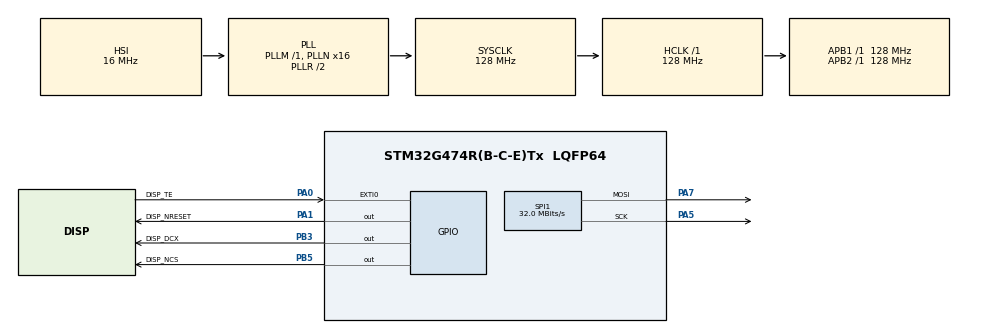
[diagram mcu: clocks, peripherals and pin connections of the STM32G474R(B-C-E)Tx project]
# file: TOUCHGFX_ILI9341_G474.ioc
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Dma.Request0=SPI1_TX
Dma.SPI1_TX.0.Direction=DMA_MEMORY_TO_PERIPH
Dma.SPI1_TX.0.EventEnable=DISABLE
Dma.SPI1_TX.0.Instance=DMA1_Channel1
Dma.SPI1_TX.0.MemDataAlignment=DMA_MDATAALIGN_HALFWORD
Dma.SPI1_TX.0.MemInc=DMA_MINC_ENABLE
Dma.SPI1_TX.0.Mode=DMA_NORMAL
Dma.SPI1_TX.0.PeriphDataAlignment=DMA_PDATAALIGN_HALFWORD
Dma.SPI1_TX.0.PeriphInc=DMA_PINC_DISABLE
Dma.SPI1_TX.0.Polarity=HAL_DMAMUX_REQ_GEN_RISING
Dma.SPI1_TX.0.Priority=DMA_PRIORITY_LOW
Dma.SPI1_TX.0.RequestNumber=1
Dma.SPI1_TX.0.SignalID=NONE
Dma.SPI1_TX.0.SyncEnable=DISABLE
Dma.SPI1_TX.0.SyncPolarity=HAL_DMAMUX_SYNC_NO_EVENT
Dma.SPI1_TX.0.SyncRequestNumber=1
Dma.SPI1_TX.0.SyncSignalID=NONE
Mcu.Family=STM32G4
Mcu.Name=STM32G474R(B-C-E)Tx
Mcu.Package=LQFP64
NVIC.DMA1_Channel1_IRQn=true\:0\:0\:false\:false\:true\:false\:true\:true
NVIC.EXTI0_IRQn=true\:0\:0\:false\:false\:true\:true\:true\:true
NVIC.PriorityGroup=NVIC_PRIORITYGROUP_4
PA0.GPIO_Label=DISP_TE
PA0.GPIO_ModeDefaultEXTI=GPIO_MODE_IT_RISING_FALLING
PA0.Signal=GPXTI0
PA1.GPIO_Label=DISP_NRESET
PA1.GPIO_PuPd=GPIO_PULLUP
PA1.GPIO_Speed=GPIO_SPEED_FREQ_VERY_HIGH
PA1.Signal=GPIO_Output
PA5.GPIO_Mode=GPIO_MODE_AF_PP
PA5.GPIO_PuPd=GPIO_PULLDOWN
PA5.GPIO_Speed=GPIO_SPEED_FREQ_HIGH
PA5.Mode=TX_Only_Simplex_Unidirect_Master
PA5.Signal=SPI1_SCK
PA7.GPIO_Mode=GPIO_MODE_AF_PP
PA7.GPIO_PuPd=GPIO_PULLDOWN
PA7.GPIO_Speed=GPIO_SPEED_FREQ_HIGH
PA7.Mode=TX_Only_Simplex_Unidirect_Master
PA7.Signal=SPI1_MOSI
PB3.GPIO_Label=DISP_DCX
PB3.GPIO_PuPd=GPIO_PULLUP
PB3.GPIO_Speed=GPIO_SPEED_FREQ_VERY_HIGH
PB3.PinState=GPIO_PIN_SET
PB3.Signal=GPIO_Output
PB5.GPIO_Label=DISP_NCS
PB5.GPIO_PuPd=GPIO_PULLUP
PB5.GPIO_Speed=GPIO_SPEED_FREQ_VERY_HIGH
PB5.PinState=GPIO_PIN_SET
PB5.Signal=GPIO_Output
ProjectManager.HeapSize=0x200
ProjectManager.StackSize=0x400
ProjectManager.TargetToolchain=STM32CubeIDE
RCC.ADC12Freq_Value=128000000
RCC.ADC345Freq_Value=128000000
RCC.AHBFreq_Value=128000000
RCC.APB1Freq_Value=128000000
RCC.APB1TimFreq_Value=128000000
RCC.APB2Freq_Value=128000000
RCC.APB2TimFreq_Value=128000000
RCC.CortexFreq_Value=128000000
RCC.EXTERNAL_CLOCK_VALUE=12288000
RCC.HCLKFreq_Value=128000000
RCC.HSE_VALUE=8000000
RCC.HSI48_VALUE=48000000
RCC.HSI_VALUE=16000000
RCC.LSE_VALUE=32768
RCC.PLLN=16
RCC.SYSCLKFreq_VALUE=128000000
RCC.SYSCLKSource=RCC_SYSCLKSOURCE_PLLCLK
RCC.USBFreq_Value=128000000
RCC.VCOOutputFreq_Value=256000000
SPI1.BaudRatePrescaler=SPI_BAUDRATEPRESCALER_4
SPI1.CalculateBaudRate=32.0 MBits/s
SPI1.DataSize=SPI_DATASIZE_8BIT
SPI1.Direction=SPI_DIRECTION_2LINES
SPI1.Mode=SPI_MODE_MASTER
SPI1.VirtualType=VM_MASTER
STMicroelectronics.X-CUBE-TOUCHGFX.4.21.4.ApplicationCcGraphicsJjApplication=TouchGFXOoGenerator
STMicroelectronics.X-CUBE-TOUCHGFX.4.21.4.tgfx_block_size=9600
STMicroelectronics.X-CUBE-TOUCHGFX.4.21.4.tgfx_buffering_strategy=Partial
STMicroelectronics.X-CUBE-TOUCHGFX.4.21.4.tgfx_custom_height=320
STMicroelectronics.X-CUBE-TOUCHGFX.4.21.4.tgfx_custom_width=240
STMicroelectronics.X-CUBE-TOUCHGFX.4.21.4.tgfx_partialfb_transmit_strategy=Enabled
STMicroelectronics.X-CUBE-TOUCHGFX.4.21.4_IsPackSelfContextualization=true
TIM6.Prescaler=5041
TIM6.TIM_MasterOutputTrigger=TIM_TRGO_ENABLE
VP_CRC_VS_CRC.Mode=CRC_Activate
VP_STMicroelectronics.X-CUBE-TOUCHGFX_VS_GraphicsJjApplication_4.21.4.Mode=GraphicsJjApplication
VP_TIM6_VS_ClockSourceINT.Mode=Enable_Timer
board=custom

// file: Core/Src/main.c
/* USER CODE BEGIN Header */
/**
  ******************************************************************************
  * @file           : main.c
  * @brief          : Main program body
  ******************************************************************************
  * @attention
  *
  * Copyright (c) 2023 STMicroelectronics.
  * All rights reserved.
  *
  * This software is licensed under terms that can be found in the LICENSE file
  * in the root directory of this software component.
  * If no LICENSE file comes with this software, it is provided AS-IS.
  *
  ******************************************************************************
  */
/* USER CODE END Header */
#include "main.h"
#include "app_touchgfx.h"

/* USER CODE BEGIN PD */
#define USE_DMA 				1
/* USER CODE END PD */

CRC_HandleTypeDef hcrc;

SPI_HandleTypeDef hspi1;
DMA_HandleTypeDef hdma_spi1_tx;

TIM_HandleTypeDef htim6;

void SystemClock_Config(void);
static void MX_GPIO_Init(void);
static void MX_DMA_Init(void);
static void MX_SPI1_Init(void);
static void MX_CRC_Init(void);
static void MX_TIM6_Init(void);

int main(void)
{

  /* MCU Configuration--------------------------------------------------------*/

  /* Reset of all peripherals, Initializes the Flash interface and the Systick. */
  HAL_Init();

  /* Configure the system clock */
  SystemClock_Config();

  /* Initialize all configured peripherals */
  MX_GPIO_Init();
  MX_DMA_Init();
  MX_SPI1_Init();
  MX_CRC_Init();
  MX_TIM6_Init();
  MX_TouchGFX_Init();

  /* Infinite loop */
  while (1)
  {

  MX_TouchGFX_Process();
  }
}

void SystemClock_Config(void)
{
  RCC_OscInitTypeDef RCC_OscInitStruct = {0};
  RCC_ClkInitTypeDef RCC_ClkInitStruct = {0};

  /** Configure the main internal regulator output voltage
  */
  HAL_PWREx_ControlVoltageScaling(PWR_REGULATOR_VOLTAGE_SCALE1);

  /** Initializes the RCC Oscillators according to the specified parameters
  * in the RCC_OscInitTypeDef structure.
  */
  RCC_OscInitStruct.OscillatorType = RCC_OSCILLATORTYPE_HSI;
  RCC_OscInitStruct.HSIState = RCC_HSI_ON;
  RCC_OscInitStruct.HSICalibrationValue = RCC_HSICALIBRATION_DEFAULT;
  RCC_OscInitStruct.PLL.PLLState = RCC_PLL_ON;
  RCC_OscInitStruct.PLL.PLLSource = RCC_PLLSOURCE_HSI;
  RCC_OscInitStruct.PLL.PLLM = RCC_PLLM_DIV1;
  RCC_OscInitStruct.PLL.PLLN = 16;
  RCC_OscInitStruct.PLL.PLLP = RCC_PLLP_DIV2;
  RCC_OscInitStruct.PLL.PLLQ = RCC_PLLQ_DIV2;
  RCC_OscInitStruct.PLL.PLLR = RCC_PLLR_DIV2;
  if (HAL_RCC_OscConfig(&RCC_OscInitStruct) != HAL_OK)
  {
    Error_Handler();
  }

  /** Initializes the CPU, AHB and APB buses clocks
  */
  RCC_ClkInitStruct.ClockType = RCC_CLOCKTYPE_HCLK|RCC_CLOCKTYPE_SYSCLK
                              |RCC_CLOCKTYPE_PCLK1|RCC_CLOCKTYPE_PCLK2;
  RCC_ClkInitStruct.SYSCLKSource = RCC_SYSCLKSOURCE_PLLCLK;
  RCC_ClkInitStruct.AHBCLKDivider = RCC_SYSCLK_DIV1;
  RCC_ClkInitStruct.APB1CLKDivider = RCC_HCLK_DIV1;
  RCC_ClkInitStruct.APB2CLKDivider = RCC_HCLK_DIV1;

  if (HAL_RCC_ClockConfig(&RCC_ClkInitStruct, FLASH_LATENCY_4) != HAL_OK)
  {
    Error_Handler();
  }
}

static void MX_CRC_Init(void)
{

  hcrc.Instance = CRC;
  hcrc.Init.DefaultPolynomialUse = DEFAULT_POLYNOMIAL_ENABLE;
  hcrc.Init.DefaultInitValueUse = DEFAULT_INIT_VALUE_ENABLE;
  hcrc.Init.InputDataInversionMode = CRC_INPUTDATA_INVERSION_NONE;
  hcrc.Init.OutputDataInversionMode = CRC_OUTPUTDATA_INVERSION_DISABLE;
  hcrc.InputDataFormat = CRC_INPUTDATA_FORMAT_BYTES;
  if (HAL_CRC_Init(&hcrc) != HAL_OK)
  {
    Error_Handler();
  }

}

static void MX_SPI1_Init(void)
{

  /* SPI1 parameter configuration*/
  hspi1.Instance = SPI1;
  hspi1.Init.Mode = SPI_MODE_MASTER;
  hspi1.Init.Direction = SPI_DIRECTION_2LINES;
  hspi1.Init.DataSize = SPI_DATASIZE_8BIT;
  hspi1.Init.CLKPolarity = SPI_POLARITY_LOW;
  hspi1.Init.CLKPhase = SPI_PHASE_1EDGE;
  hspi1.Init.NSS = SPI_NSS_SOFT;
  hspi1.Init.BaudRatePrescaler = SPI_BAUDRATEPRESCALER_4;
  hspi1.Init.FirstBit = SPI_FIRSTBIT_MSB;
  hspi1.Init.TIMode = SPI_TIMODE_DISABLE;
  hspi1.Init.CRCCalculation = SPI_CRCCALCULATION_DISABLE;
  hspi1.Init.CRCPolynomial = 7;
  hspi1.Init.CRCLength = SPI_CRC_LENGTH_DATASIZE;
  hspi1.Init.NSSPMode = SPI_NSS_PULSE_ENABLE;
  if (HAL_SPI_Init(&hspi1) != HAL_OK)
  {
    Error_Handler();
  }

}

static void MX_TIM6_Init(void)
{

  TIM_MasterConfigTypeDef sMasterConfig = {0};

  htim6.Instance = TIM6;
  htim6.Init.Prescaler = 5041;
  htim6.Init.CounterMode = TIM_COUNTERMODE_UP;
  htim6.Init.Period = 65535;
  htim6.Init.AutoReloadPreload = TIM_AUTORELOAD_PRELOAD_DISABLE;
  if (HAL_TIM_Base_Init(&htim6) != HAL_OK)
  {
    Error_Handler();
  }
  sMasterConfig.MasterOutputTrigger = TIM_TRGO_ENABLE;
  sMasterConfig.MasterSlaveMode = TIM_MASTERSLAVEMODE_DISABLE;
  if (HAL_TIMEx_MasterConfigSynchronization(&htim6, &sMasterConfig) != HAL_OK)
  {
    Error_Handler();
  }

}

static void MX_DMA_Init(void)
{

  /* DMA controller clock enable */
  __HAL_RCC_DMAMUX1_CLK_ENABLE();
  __HAL_RCC_DMA1_CLK_ENABLE();

  /* DMA interrupt init */
  /* DMA1_Channel1_IRQn interrupt configuration */
  HAL_NVIC_SetPriority(DMA1_Channel1_IRQn, 0, 0);
  HAL_NVIC_EnableIRQ(DMA1_Channel1_IRQn);

}

static void MX_GPIO_Init(void)
{
  GPIO_InitTypeDef GPIO_InitStruct = {0};

  /* GPIO Ports Clock Enable */
  __HAL_RCC_GPIOA_CLK_ENABLE();
  __HAL_RCC_GPIOB_CLK_ENABLE();

  /*Configure GPIO pin Output Level */
  HAL_GPIO_WritePin(DISP_NRESET_GPIO_Port, DISP_NRESET_Pin, GPIO_PIN_RESET);

  /*Configure GPIO pin Output Level */
  HAL_GPIO_WritePin(GPIOB, DISP_DCX_Pin|DISP_NCS_Pin, GPIO_PIN_SET);

  /*Configure GPIO pin : DISP_TE_Pin */
  GPIO_InitStruct.Pin = DISP_TE_Pin;
  GPIO_InitStruct.Mode = GPIO_MODE_IT_RISING_FALLING;
  GPIO_InitStruct.Pull = GPIO_NOPULL;
  HAL_GPIO_Init(DISP_TE_GPIO_Port, &GPIO_InitStruct);

  /*Configure GPIO pin : DISP_NRESET_Pin */
  GPIO_InitStruct.Pin = DISP_NRESET_Pin;
  GPIO_InitStruct.Mode = GPIO_MODE_OUTPUT_PP;
  GPIO_InitStruct.Pull = GPIO_PULLUP;
  GPIO_InitStruct.Speed = GPIO_SPEED_FREQ_VERY_HIGH;
  HAL_GPIO_Init(DISP_NRESET_GPIO_Port, &GPIO_InitStruct);

  /*Configure GPIO pins : DISP_DCX_Pin DISP_NCS_Pin */
  GPIO_InitStruct.Pin = DISP_DCX_Pin|DISP_NCS_Pin;
  GPIO_InitStruct.Mode = GPIO_MODE_OUTPUT_PP;
  GPIO_InitStruct.Pull = GPIO_PULLUP;
  GPIO_InitStruct.Speed = GPIO_SPEED_FREQ_VERY_HIGH;
  HAL_GPIO_Init(GPIOB, &GPIO_InitStruct);

  /* EXTI interrupt init*/
  HAL_NVIC_SetPriority(EXTI0_IRQn, 0, 0);
  HAL_NVIC_EnableIRQ(EXTI0_IRQn);

}

void Error_Handler(void)
{
  __disable_irq();
  while (1)
  {
  }
}
